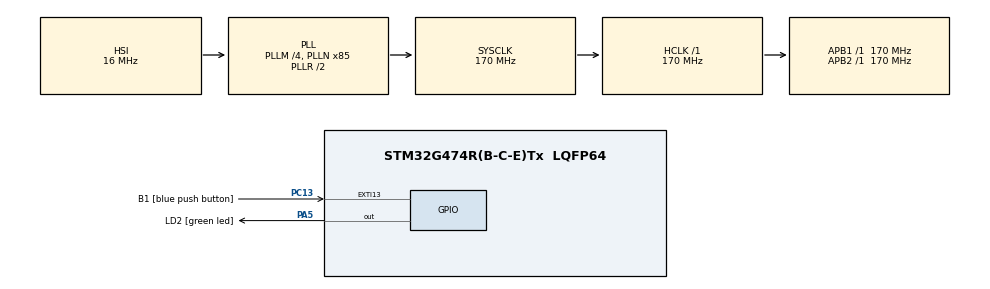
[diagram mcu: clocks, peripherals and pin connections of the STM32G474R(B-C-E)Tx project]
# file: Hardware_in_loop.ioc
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Mcu.Family=STM32G4
Mcu.Name=STM32G474R(B-C-E)Tx
Mcu.Package=LQFP64
NVIC.EXTI15_10_IRQn=true\:0\:0\:false\:false\:true\:true\:true\:true
NVIC.PriorityGroup=NVIC_PRIORITYGROUP_4
NVIC.TIM2_IRQn=true\:0\:0\:false\:false\:true\:true\:true\:true
PA13.GPIO_Label=T_SWDIO
PA13.Mode=Trace_Asynchronous_SW
PA13.Signal=SYS_JTMS-SWDIO
PA14.GPIO_Label=T_SWCLK
PA14.Mode=Trace_Asynchronous_SW
PA14.Signal=SYS_JTCK-SWCLK
PA2.GPIO_Label=LPUART1_TX [STLINKV3E_VCP_RX]
PA2.Signal=LPUART1_TX
PA3.GPIO_Label=LPUART1_RX [STLINKV3E_VCP_TX]
PA3.Signal=LPUART1_RX
PA5.GPIO_Label=LD2 [green led]
PA5.Signal=GPIO_Output
PB3.GPIO_Label=T_SWO
PB3.Mode=Trace_Asynchronous_SW
PB3.Signal=SYS_JTDO-SWO
PC13.GPIO_Label=B1 [blue push button]
PC13.Signal=GPXTI13
PC14-OSC32_IN.GPIO_Label=RCC_OSC32_IN
PC14-OSC32_IN.Signal=RCC_OSC32_IN
PC15-OSC32_OUT.GPIO_Label=RCC_OSC32_OUT
PC15-OSC32_OUT.Signal=RCC_OSC32_OUT
PF0-OSC_IN.GPIO_Label=RCC_OSC_IN
PF0-OSC_IN.Signal=RCC_OSC_IN
PF1-OSC_OUT.GPIO_Label=RCC_OSC_OUT
PF1-OSC_OUT.Signal=RCC_OSC_OUT
ProjectManager.HeapSize=0x200
ProjectManager.StackSize=0x400
ProjectManager.TargetToolchain=STM32CubeIDE
RCC.ADC12Freq_Value=170000000
RCC.ADC345Freq_Value=170000000
RCC.AHBFreq_Value=170000000
RCC.APB1Freq_Value=170000000
RCC.APB1TimFreq_Value=170000000
RCC.APB2Freq_Value=170000000
RCC.APB2TimFreq_Value=170000000
RCC.CortexFreq_Value=170000000
RCC.EXTERNAL_CLOCK_VALUE=12288000
RCC.HCLKFreq_Value=170000000
RCC.HSE_VALUE=24000000
RCC.HSI48_VALUE=48000000
RCC.HSI_VALUE=16000000
RCC.LSE_VALUE=32768
RCC.PLLM=RCC_PLLM_DIV4
RCC.PLLN=85
RCC.RTCClockSelection=RCC_RTCCLKSOURCE_LSE
RCC.SYSCLKFreq_VALUE=170000000
RCC.SYSCLKSource=RCC_SYSCLKSOURCE_PLLCLK
RCC.USBFreq_Value=170000000
RCC.VCOOutputFreq_Value=340000000
TIM2.PeriodNoDither=9
TIM2.Prescaler=169
VP_SYS_VS_DBSignals.Mode=DisableDeadBatterySignals
VP_TIM2_VS_ClockSourceINT.Mode=Internal
board=NUCLEO-G474RE

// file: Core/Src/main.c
/* USER CODE BEGIN Header */
/**
  ******************************************************************************
  * @file           : main.c
  * @brief          : Main program body
  ******************************************************************************
  * @attention
  *
  * Copyright (c) 2026 STMicroelectronics.
  * All rights reserved.
  *
  * This software is licensed under terms that can be found in the LICENSE file
  * in the root directory of this software component.
  * If no LICENSE file comes with this software, it is provided AS-IS.
  *
  ******************************************************************************
  */
/* USER CODE END Header */
#include "main.h"
#include "tim.h"
#include "gpio.h"

/* USER CODE BEGIN Includes */
#include "DiscreteMotor.h"

#define PARAM_n   0.9994f     // Gear ratio
#define PARAM_Ke  0.05072f    // Back EMF constant (V/(rad/s))
#define PARAM_J   0.000011211   // Rotor inertia (kg.m^2)
#define PARAM_L   0.00003622f     // Armature inductance (H)
#define PARAM_b   0.0000327239    // Viscous friction (N.m.s)
#define PARAM_Rm  3.74f     // Armature resistance (Ohms)
#define TS        0.001f   // Sampling time 1 ms

#include <cmath>
#include <iostream>
/* USER CODE END Includes */

/* USER CODE BEGIN PV */
uint32_t testing = 0;

volatile float current_voltage = 12.0f; // สมมติว่าป้อนไฟ 5V
volatile float motor_speed_tustin = 0.0f;
volatile float motor_speed_Forward = 0.0f;
volatile float motor_speed_Backward = 0.0f;

volatile float t = 0.0;

DiscreteMotor motorModel(PARAM_n, PARAM_Ke, PARAM_J, PARAM_L, PARAM_b, PARAM_Rm, TS);

/* USER CODE END PV */

void SystemClock_Config(void);
/* USER CODE BEGIN PFP */
double sineFunc(float a,float t,float f);
double rampFunc(float slope, float t, float start_time);
float pulseTrainFunc(float amplitude, float t, float start_time, float period, float duty_cycle, int num_pulses);
/* USER CODE END PFP */

int main(void)
{

  /* MCU Configuration--------------------------------------------------------*/

  /* Reset of all peripherals, Initializes the Flash interface and the Systick. */
  HAL_Init();

  /* Configure the system clock */
  SystemClock_Config();

  /* Initialize all configured peripherals */
  MX_GPIO_Init();
  MX_TIM2_Init();
  /* USER CODE BEGIN 2 */
  HAL_TIM_Base_Start_IT(&htim2);

  /* USER CODE END 2 */

  /* Infinite loop */
  while (1)
  {

  }
}

void SystemClock_Config(void)
{
  RCC_OscInitTypeDef RCC_OscInitStruct = {0};
  RCC_ClkInitTypeDef RCC_ClkInitStruct = {0};

  /** Configure the main internal regulator output voltage
  */
  HAL_PWREx_ControlVoltageScaling(PWR_REGULATOR_VOLTAGE_SCALE1_BOOST);

  /** Initializes the RCC Oscillators according to the specified parameters
  * in the RCC_OscInitTypeDef structure.
  */
  RCC_OscInitStruct.OscillatorType = RCC_OSCILLATORTYPE_HSI;
  RCC_OscInitStruct.HSIState = RCC_HSI_ON;
  RCC_OscInitStruct.HSICalibrationValue = RCC_HSICALIBRATION_DEFAULT;
  RCC_OscInitStruct.PLL.PLLState = RCC_PLL_ON;
  RCC_OscInitStruct.PLL.PLLSource = RCC_PLLSOURCE_HSI;
  RCC_OscInitStruct.PLL.PLLM = RCC_PLLM_DIV4;
  RCC_OscInitStruct.PLL.PLLN = 85;
  RCC_OscInitStruct.PLL.PLLP = RCC_PLLP_DIV2;
  RCC_OscInitStruct.PLL.PLLQ = RCC_PLLQ_DIV2;
  RCC_OscInitStruct.PLL.PLLR = RCC_PLLR_DIV2;
  if (HAL_RCC_OscConfig(&RCC_OscInitStruct) != HAL_OK)
  {
    Error_Handler();
  }

  /** Initializes the CPU, AHB and APB buses clocks
  */
  RCC_ClkInitStruct.ClockType = RCC_CLOCKTYPE_HCLK|RCC_CLOCKTYPE_SYSCLK
                              |RCC_CLOCKTYPE_PCLK1|RCC_CLOCKTYPE_PCLK2;
  RCC_ClkInitStruct.SYSCLKSource = RCC_SYSCLKSOURCE_PLLCLK;
  RCC_ClkInitStruct.AHBCLKDivider = RCC_SYSCLK_DIV1;
  RCC_ClkInitStruct.APB1CLKDivider = RCC_HCLK_DIV1;
  RCC_ClkInitStruct.APB2CLKDivider = RCC_HCLK_DIV1;

  if (HAL_RCC_ClockConfig(&RCC_ClkInitStruct, FLASH_LATENCY_4) != HAL_OK)
  {
    Error_Handler();
  }
}

/* USER CODE BEGIN 4 */
void HAL_TIM_PeriodElapsedCallback(TIM_HandleTypeDef *htim)
 {
	if (htim == &htim2) {
//		float v_in = sineFunc(12, t/1000, 1);
//		float v_in = rampFunc(1,t/1000,1);
		float v_in = pulseTrainFunc(12, t/1000, 1, 2, 0.5, 10);
		motor_speed_tustin = motorModel.updateTustin(v_in);
//		motor_speed_Forward = motorModel.updateForward(v_in);
//		motor_speed_Backward = motorModel.updateBackward(v_in);
//		std::cout << "%d" << motor_speed_tustin << "\n";
		t++;
	}
}

double sineFunc(float a,float t,float f){
	return a*sin(2*(22/7)*f*t);
}

double rampFunc(float slope, float t, float start_time) {
    if (t >= start_time) {
        return slope * (t - start_time);
    } else {
        return 0.0f;
    }
}

float pulseTrainFunc(float amplitude, float t, float start_time, float period, float duty_cycle, int num_pulses) {
    if (t < start_time) {
        return 0.0f; // ยังไม่ถึงเวลาเริ่มต้น
    }

    float t_active = t - start_time;
    int current_pulse = (int)(t_active / period); // คำนวณว่าตอนนี้อยู่ลูกคลื่นที่เท่าไหร่

    // ถ้าจ่ายคลื่นครบจำนวนลูกที่กำหนดแล้ว ให้หยุดจ่าย (กลับเป็น 0)
    if (current_pulse >= num_pulses) {
        return 0.0f;
    }

    // คำนวณเวลาที่อยู่ในลูกคลื่นปัจจุบัน
    float t_in_period = t_active - (current_pulse * period);

    // จ่าย High ตามสัดส่วน Duty Cycle (เช่น 0.5 คือ High ครึ่งนึง Low ครึ่งนึง)
    if (t_in_period < (period * duty_cycle)) {
        return amplitude;
    } else {
        return 0.0f;
    }
}

int _write(int file, char *ptr, int len) {
	int i;
	for (i = 0; i < len; i++) {
		ITM_SendChar(*ptr++);
	}
	return len;
}
/* USER CODE END 4 */

void Error_Handler(void)
{
  __disable_irq();
  while (1)
  {
  }
}
